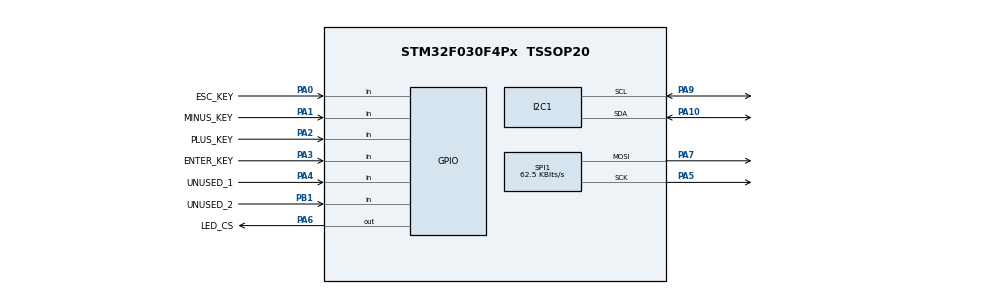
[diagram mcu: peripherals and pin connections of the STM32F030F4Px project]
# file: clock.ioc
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CRC.DefaultInitValueUse=DEFAULT_INIT_VALUE_ENABLE
I2C1.Timing=0x00503D58
IWDG.Reload=1000
Mcu.Family=STM32F0
Mcu.Name=STM32F030F4Px
Mcu.Package=TSSOP20
Mcu.UserConstants=KEYBOARD_DEBOUNCE_TIME,20;UPDATE_FREQUENCY,32
NVIC.TIM14_IRQn=true\:0\:0\:false\:false\:true\:true\:true\:true
PA0.GPIO_Label=ESC_KEY
PA0.GPIO_PuPd=GPIO_PULLUP
PA0.Signal=GPIO_Input
PA1.GPIO_Label=MINUS_KEY
PA1.GPIO_PuPd=GPIO_PULLUP
PA1.Signal=GPIO_Input
PA10.Mode=I2C
PA10.Signal=I2C1_SDA
PA13.Mode=Serial_Wire
PA13.Signal=SYS_SWDIO
PA14.Mode=Serial_Wire
PA14.Signal=SYS_SWCLK
PA2.GPIO_Label=PLUS_KEY
PA2.GPIO_PuPd=GPIO_PULLUP
PA2.Signal=GPIO_Input
PA3.GPIO_Label=ENTER_KEY
PA3.GPIO_PuPd=GPIO_PULLUP
PA3.Signal=GPIO_Input
PA4.GPIO_Label=UNUSED_1
PA4.GPIO_PuPd=GPIO_PULLUP
PA4.Signal=GPIO_Input
PA5.Mode=TX_Only_Simplex_Unidirect_Master
PA5.Signal=SPI1_SCK
PA6.GPIO_Label=LED_CS
PA6.GPIO_Speed=GPIO_SPEED_FREQ_HIGH
PA6.PinState=GPIO_PIN_SET
PA6.Signal=GPIO_Output
PA7.Mode=TX_Only_Simplex_Unidirect_Master
PA7.Signal=SPI1_MOSI
PA9.Mode=I2C
PA9.Signal=I2C1_SCL
PB1.GPIO_Label=UNUSED_2
PB1.GPIO_PuPd=GPIO_PULLUP
PB1.Signal=GPIO_Input
PF0-OSC_IN.Mode=HSE-External-Oscillator
PF0-OSC_IN.Signal=RCC_OSC_IN
PF1-OSC_OUT.Mode=HSE-External-Oscillator
PF1-OSC_OUT.Signal=RCC_OSC_OUT
ProjectManager.HeapSize=0x200
ProjectManager.StackSize=0x400
ProjectManager.TargetToolchain=STM32CubeIDE
RCC.AHBFreq_Value=16000000
RCC.APB1Freq_Value=16000000
RCC.APB1TimFreq_Value=16000000
RCC.HCLKFreq_Value=16000000
RCC.HSE_Timout=100
RCC.I2c1ClockSelection=RCC_I2C1CLKSOURCE_SYSCLK
RCC.PLLSourceVirtual=RCC_PLLSOURCE_HSE
RCC.SYSCLKFreq_VALUE=16000000
RCC.SYSCLKSource=RCC_SYSCLKSOURCE_PLLCLK
SPI1.BaudRatePrescaler=SPI_BAUDRATEPRESCALER_256
SPI1.CalculateBaudRate=62.5 KBits/s
SPI1.DataSize=SPI_DATASIZE_8BIT
SPI1.Direction=SPI_DIRECTION_2LINES
SPI1.Mode=SPI_MODE_MASTER
SPI1.NSSPMode=SPI_NSS_PULSE_DISABLE
SPI1.VirtualType=VM_MASTER
TIM14.Period=3125
TIM14.Prescaler=159
TIM17.Prescaler=15999
VP_CRC_VS_CRC.Mode=CRC_Activate
VP_IWDG_VS_IWDG.Mode=IWDG_Activate
VP_TIM14_VS_ClockSourceINT.Mode=Enable_Timer
VP_TIM17_VS_ClockSourceINT.Mode=Enable_Timer
board=custom

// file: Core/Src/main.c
/* USER CODE BEGIN Header */
/**
  ******************************************************************************
  * @file           : main.c
  * @brief          : Main program body
  ******************************************************************************
  * @attention
  *
  * Copyright (c) 2025 STMicroelectronics.
  * All rights reserved.
  *
  * This software is licensed under terms that can be found in the LICENSE file
  * in the root directory of this software component.
  * If no LICENSE file comes with this software, it is provided AS-IS.
  *
  ******************************************************************************
  */
/* USER CODE END Header */
#include "main.h"
#include "crc.h"
#include "i2c.h"
#include "iwdg.h"
#include "spi.h"
#include "tim.h"
#include "gpio.h"

/* USER CODE BEGIN Includes */
#include "../Clock/clock.h"
/* USER CODE END Includes */

void SystemClock_Config(void);

int main(void)
{

  /* MCU Configuration--------------------------------------------------------*/

  /* Reset of all peripherals, Initializes the Flash interface and the Systick. */
  LL_APB1_GRP2_EnableClock(LL_APB1_GRP2_PERIPH_SYSCFG);
  LL_APB1_GRP1_EnableClock(LL_APB1_GRP1_PERIPH_PWR);

  /* SysTick_IRQn interrupt configuration */
  NVIC_SetPriority(SysTick_IRQn, 3);

  /* Configure the system clock */
  SystemClock_Config();

  /* Initialize all configured peripherals */
  MX_GPIO_Init();
  MX_I2C1_Init();
  MX_SPI1_Init();
  MX_TIM17_Init();
  MX_TIM14_Init();
  MX_CRC_Init();
  MX_IWDG_Init();
  /* USER CODE BEGIN 2 */
  Init();
  /* USER CODE END 2 */

  /* Infinite loop */
  /* USER CODE BEGIN WHILE */
  while (1)
  {
	Run();
    /* USER CODE END WHILE */

  }
}

void SystemClock_Config(void)
{
  LL_FLASH_SetLatency(LL_FLASH_LATENCY_0);
  while(LL_FLASH_GetLatency() != LL_FLASH_LATENCY_0)
  {
  }
  LL_RCC_HSE_Enable();

   /* Wait till HSE is ready */
  while(LL_RCC_HSE_IsReady() != 1)
  {

  }
  LL_RCC_LSI_Enable();

   /* Wait till LSI is ready */
  while(LL_RCC_LSI_IsReady() != 1)
  {

  }
  LL_RCC_PLL_ConfigDomain_SYS(LL_RCC_PLLSOURCE_HSE_DIV_1, LL_RCC_PLL_MUL_2);
  LL_RCC_PLL_Enable();

   /* Wait till PLL is ready */
  while(LL_RCC_PLL_IsReady() != 1)
  {

  }
  LL_RCC_SetAHBPrescaler(LL_RCC_SYSCLK_DIV_1);
  LL_RCC_SetAPB1Prescaler(LL_RCC_APB1_DIV_1);
  LL_RCC_SetSysClkSource(LL_RCC_SYS_CLKSOURCE_PLL);

   /* Wait till System clock is ready */
  while(LL_RCC_GetSysClkSource() != LL_RCC_SYS_CLKSOURCE_STATUS_PLL)
  {

  }
  LL_Init1msTick(16000000);
  LL_SetSystemCoreClock(16000000);
  LL_RCC_SetI2CClockSource(LL_RCC_I2C1_CLKSOURCE_SYSCLK);
}

void Error_Handler(void)
{
  __disable_irq();
  while (1)
  {
  }
}
